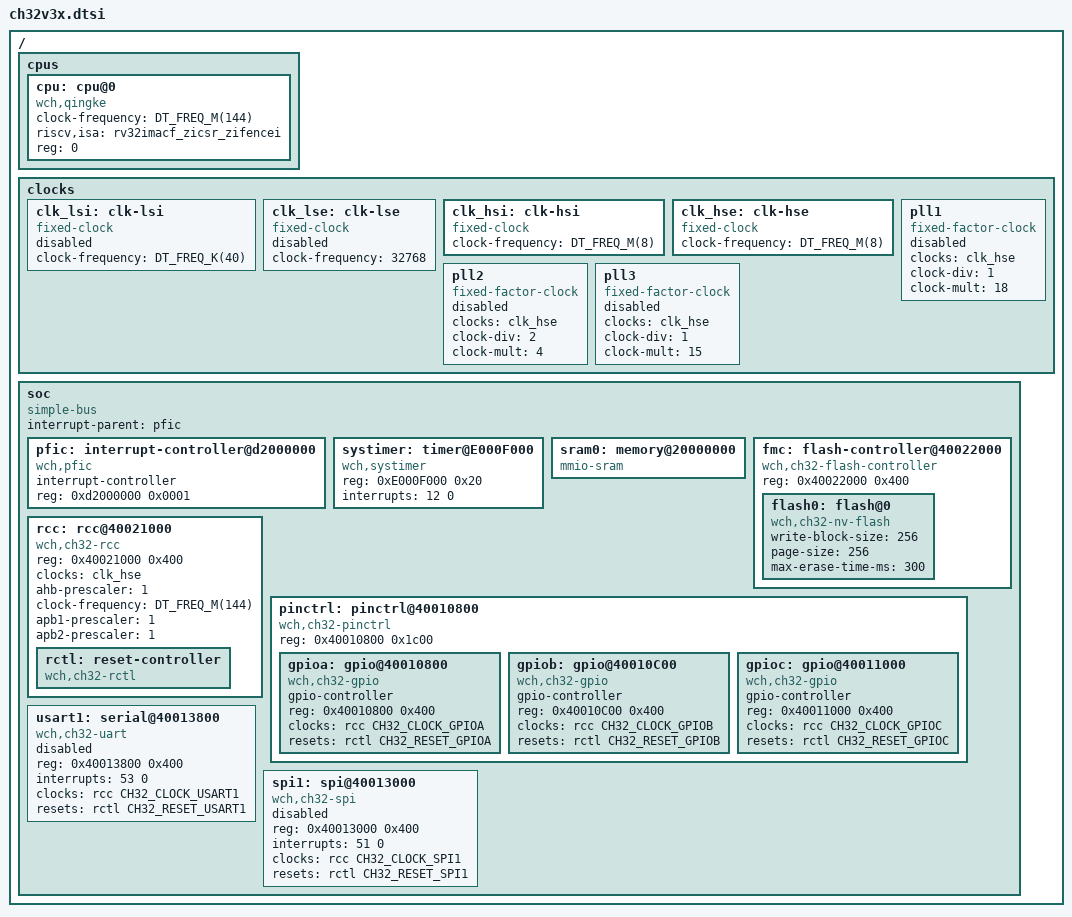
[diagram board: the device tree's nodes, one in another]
/*
 * Copyright (c)
 *
 * SPDX-License-Identifier: Apache-2.0
 */

 #include <freq.h>
 #include <mem.h>
 #include <zephyr/dt-bindings/adc/adc.h>
 #include <zephyr/dt-bindings/gpio/gpio.h>
 #include <zephyr/dt-bindings/i2c/i2c.h>
 #include <zephyr/dt-bindings/pwm/pwm.h>

 #include <zephyr/dt-bindings/clock/ch32_clock.h>
 #include <zephyr/dt-bindings/reset/ch32_reset.h>

 / {
	#address-cells = <1>;
	#size-cells = <1>;

	cpus {
		#address-cells = <1>;
		#size-cells = <0>;

		cpu: cpu@0 {
			compatible = "wch,qingke", "riscv";
			clock-frequency = <DT_FREQ_M(144)>;
			riscv,isa = "rv32imacf_zicsr_zifencei";
			reg = <0>;
		};
	};

	clocks{
		clk_lsi: clk-lsi {
			#clock-cells = <0>;
			compatible = "fixed-clock";
			clock-frequency = <DT_FREQ_K(40)>;
			status = "disabled";
		};

		clk_lse: clk-lse {
			#clock-cells = <0>;
			compatible = "fixed-clock";
			clock-frequency = <32768>;
			status = "disabled";
		};

		clk_hsi: clk-hsi {
			#clock-cells = <0>;
			compatible = "fixed-clock";
			clock-frequency = <DT_FREQ_M(8)>;
			status = "okay";
		};

		clk_hse: clk-hse {
			#clock-cells = <0>;
			compatible = "fixed-clock";
			clock-frequency = <DT_FREQ_M(8)>;
			status = "okay";
		};

		pll1: pll1 {
			compatible = "fixed-factor-clock";
			status = "disabled";
			clocks = <&clk_hse>;
			clock-div = <1>;
			clock-mult = <18>;
			#clock-cells = <0>;
		};

		pll2: pll2 {
			compatible = "fixed-factor-clock";
			status = "disabled";
			clocks = <&clk_hse>;
			clock-div = <2>;
			clock-mult = <4>;
			#clock-cells = <0>;
		};

		pll3: pll3 {
			compatible = "fixed-factor-clock";
			status = "disabled";
			clocks = <&clk_hse>;
			clock-div = <1>;
			clock-mult = <15>;
			#clock-cells = <0>;
		};
	};

    soc {
		#address-cells = <1>;
		#size-cells = <1>;
		compatible = "simple-bus";
		interrupt-parent = <&pfic>;
		ranges;

		pfic: interrupt-controller@d2000000 {
			compatible = "wch,pfic";
			#address-cells = <0>;
			#interrupt-cells = <2>;
			interrupt-controller;
			reg =  <0xd2000000 0x0001>;
		};

		systimer: timer@E000F000 {
			compatible = "wch,systimer";
			reg = <0xE000F000 0x20>;
			interrupts = <12 0>;
		};

		sram0: memory@20000000 {
			compatible = "mmio-sram";
		};

		fmc: flash-controller@40022000 {
			compatible = "wch,ch32-flash-controller";
			reg = <0x40022000 0x400>;
			#address-cells = <1>;
			#size-cells = <1>;

			flash0: flash@0 {
				compatible = "wch,ch32-nv-flash", "soc-nv-flash";
				write-block-size = <256>;
				page-size = <256>;
                max-erase-time-ms = <300>;
			};
		};

		rcc: rcc@40021000 {
			compatible = "wch,ch32-rcc";
			reg = <0x40021000 0x400>;
			#clock-cells = <1>;
			status = "okay";
			
			/* Select 144MHz pll as SYSCLK source */
			clocks = <&clk_hse>;  
			ahb-prescaler = <1>;
			/* = SYSCLK / AHB prescaler */
			/* default frequency in Hz for clock output */
			clock-frequency = <DT_FREQ_M(144)>; 
			
			apb1-prescaler = <1>;
			apb2-prescaler = <1>;

			rctl: reset-controller {
				compatible = "wch,ch32-rctl";
				#reset-cells = <1>;
				status = "okay";
			};
		};
		
		pinctrl: pinctrl@40010800 {
			compatible = "wch,ch32-pinctrl";
			reg = <0x40010800 0x1c00>;
			#address-cells = <1>;
			#size-cells = <1>;
			status = "okay";

			gpioa: gpio@40010800 {
				compatible = "wch,ch32-gpio";
				gpio-controller;
				#gpio-cells = <2>;
				reg = <0x40010800 0x400>;
				clocks = <&rcc  CH32_CLOCK_GPIOA>;
				resets = <&rctl CH32_RESET_GPIOA>;
			};

			gpiob: gpio@40010C00 {
				compatible = "wch,ch32-gpio";
				gpio-controller;
				#gpio-cells = <2>;
				reg = <0x40010C00 0x400>;
				clocks = <&rcc CH32_CLOCK_GPIOB>;
				resets = <&rctl CH32_RESET_GPIOB>;
			};

			gpioc: gpio@40011000 {
				compatible = "wch,ch32-gpio";
				gpio-controller;
				#gpio-cells = <2>;
				reg = <0x40011000 0x400>;
				clocks = <&rcc CH32_CLOCK_GPIOC>;
				resets = <&rctl CH32_RESET_GPIOC>;
			};
		};

		usart1: serial@40013800 {
			compatible = "wch,ch32-uart";
			reg = <0x40013800 0x400>;
			interrupts = <53 0>;
			clocks = <&rcc CH32_CLOCK_USART1>;
			resets = <&rctl CH32_RESET_USART1>;
			status = "disabled";
		};

		spi1: spi@40013000 {
			compatible = "wch,ch32-spi";
			reg = <0x40013000 0x400>;
			interrupts = <51 0>;
			clocks = <&rcc CH32_CLOCK_SPI1>;
			resets = <&rctl CH32_RESET_SPI1>;
			status = "disabled";
			#address-cells = <1>;
			#size-cells = <0>;
		};

		
    };

};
